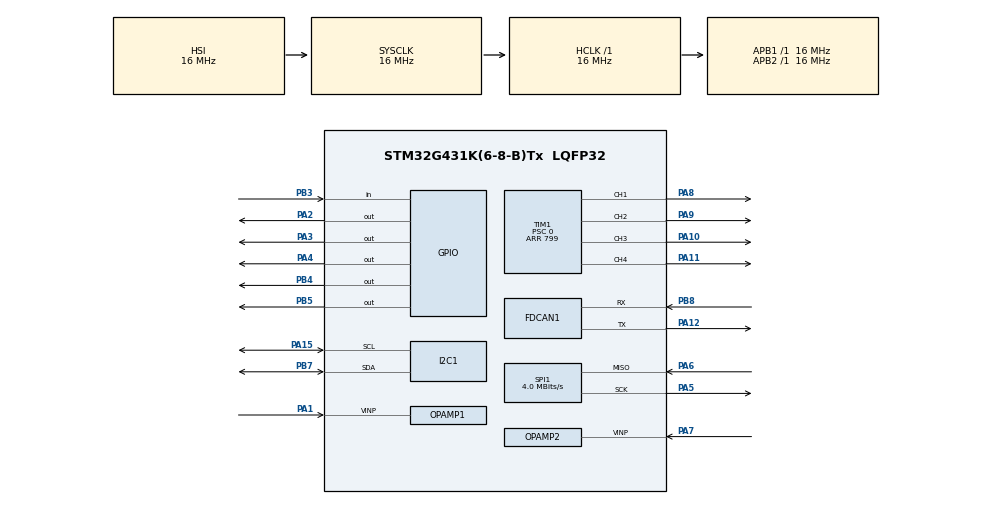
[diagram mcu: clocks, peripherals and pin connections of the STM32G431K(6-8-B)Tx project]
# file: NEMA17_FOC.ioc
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ADC1.Channel-1\#ChannelRegularConversion=ADC_CHANNEL_VOPAMP1
ADC1.NbrOfConversionFlag=1
ADC1.OffsetNumber-1\#ChannelRegularConversion=ADC_OFFSET_NONE
ADC1.Rank-1\#ChannelRegularConversion=1
ADC1.SamplingTime-1\#ChannelRegularConversion=ADC_SAMPLETIME_2CYCLES_5
ADC1.master=1
ADC2.Channel-4\#ChannelRegularConversion=ADC_CHANNEL_VOPAMP2
ADC2.NbrOfConversionFlag=1
ADC2.OffsetNumber-4\#ChannelRegularConversion=ADC_OFFSET_NONE
ADC2.Rank-4\#ChannelRegularConversion=1
ADC2.SamplingTime-4\#ChannelRegularConversion=ADC_SAMPLETIME_2CYCLES_5
FDCAN1.CalculateBaudRateNominal=333333
FDCAN1.CalculateTimeBitNominal=3000
FDCAN1.CalculateTimeQuantumNominal=1000.0
I2C1.Timing=0x00503D58
Mcu.Family=STM32G4
Mcu.Name=STM32G431K(6-8-B)Tx
Mcu.Package=LQFP32
NVIC.FDCAN1_IT0_IRQn=true\:0\:0\:false\:false\:true\:true\:true\:true
NVIC.PriorityGroup=NVIC_PRIORITYGROUP_4
NVIC.TIM2_IRQn=true\:0\:0\:false\:false\:true\:true\:true\:true
PA1.Mode=PGA_Internally_Connected
PA1.Signal=OPAMP1_VINP
PA10.Signal=S_TIM1_CH3
PA11.Signal=S_TIM1_CH4
PA12.Mode=FDCAN_Activate
PA12.Signal=FDCAN1_TX
PA13.Mode=Serial_Wire
PA13.Signal=SYS_JTMS-SWDIO
PA14.Mode=Serial_Wire
PA14.Signal=SYS_JTCK-SWCLK
PA15.Mode=I2C
PA15.Signal=I2C1_SCL
PA2.Signal=GPIO_Output
PA3.Signal=GPIO_Output
PA4.Signal=GPIO_Output
PA5.Mode=RX_Only_Simplex_Unidirect_Master
PA5.Signal=SPI1_SCK
PA6.Mode=RX_Only_Simplex_Unidirect_Master
PA6.Signal=SPI1_MISO
PA7.Mode=PGA_Internally_Connected
PA7.Signal=OPAMP2_VINP
PA8.Signal=S_TIM1_CH1
PA9.Signal=S_TIM1_CH2
PB3.Signal=GPIO_Input
PB4.Signal=GPIO_Output
PB5.Signal=GPIO_Output
PB7.Mode=I2C
PB7.Signal=I2C1_SDA
PB8-BOOT0.Mode=FDCAN_Activate
PB8-BOOT0.Signal=FDCAN1_RX
ProjectManager.HeapSize=0x200
ProjectManager.StackSize=0x400
ProjectManager.TargetToolchain=CMake
RCC.AHBFreq_Value=16000000
RCC.APB1Freq_Value=16000000
RCC.APB1TimFreq_Value=16000000
RCC.APB2Freq_Value=16000000
RCC.APB2TimFreq_Value=16000000
RCC.CortexFreq_Value=16000000
RCC.EXTERNAL_CLOCK_VALUE=12288000
RCC.HCLKFreq_Value=16000000
RCC.HSE_VALUE=8000000
RCC.HSI48_VALUE=48000000
RCC.HSI_VALUE=16000000
RCC.LSE_VALUE=32768
RCC.SYSCLKFreq_VALUE=16000000
RCC.USBFreq_Value=64000000
RCC.VCOOutputFreq_Value=128000000
SH.S_TIM1_CH1.0=TIM1_CH1,PWM Generation1 CH1
SH.S_TIM1_CH2.0=TIM1_CH2,PWM Generation2 CH2
SH.S_TIM1_CH3.0=TIM1_CH3,PWM Generation3 CH3
SH.S_TIM1_CH4.0=TIM1_CH4,PWM Generation4 CH4
SPI1.BaudRatePrescaler=SPI_BAUDRATEPRESCALER_4
SPI1.CLKPhase=SPI_PHASE_2EDGE
SPI1.CLKPolarity=SPI_POLARITY_HIGH
SPI1.CalculateBaudRate=4.0 MBits/s
SPI1.DataSize=SPI_DATASIZE_8BIT
SPI1.Direction=SPI_DIRECTION_2LINES_RXONLY
SPI1.Mode=SPI_MODE_MASTER
SPI1.VirtualType=VM_MASTER
TIM1.AutoReloadPreload=TIM_AUTORELOAD_PRELOAD_ENABLE
TIM1.Channel-PWM\ Generation1\ CH1=TIM_CHANNEL_1
TIM1.Channel-PWM\ Generation2\ CH2=TIM_CHANNEL_2
TIM1.Channel-PWM\ Generation3\ CH3=TIM_CHANNEL_3
TIM1.Channel-PWM\ Generation4\ CH4=TIM_CHANNEL_4
TIM1.CounterMode=TIM_COUNTERMODE_CENTERALIGNED1
TIM1.PeriodNoDither=799
TIM1.Prescaler=0
TIM2.PeriodNoDither=3999
TIM2.Prescaler=999
VP_ADC1_OPAMP_INTERNAL1.Mode=IN-OPAMP1
VP_ADC2_OPAMP_INTERNAL2.Mode=IN-OPAMP2
VP_CORDIC_VS_CORDIC.Mode=CORDIC_Activate
VP_SYS_VS_DBSignals.Mode=DisableDeadBatterySignals
VP_SYS_V_PVD_IN.Mode=Mode_PVD_Int
VP_TIM1_VS_ClockSourceINT.Mode=Internal
VP_TIM2_VS_ClockSourceINT.Mode=Internal
board=custom

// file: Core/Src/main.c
/* USER CODE BEGIN Header */
/**
  ******************************************************************************
  * @file           : main.c
  * @brief          : Main program body
  ******************************************************************************
  * @attention
  *
  * Copyright (c) 2026 STMicroelectronics.
  * All rights reserved.
  *
  * This software is licensed under terms that can be found in the LICENSE file
  * in the root directory of this software component.
  * If no LICENSE file comes with this software, it is provided AS-IS.
  *
  ******************************************************************************
  */
/* USER CODE END Header */
#include "main.h"

/* USER CODE BEGIN PD */
#define PWM_RANGE 1000   // Muss dem ARR Wert im CubeMX entsprechen
#define STEP_SPEED 0.01f // Erhöhen für schnellere Drehung
/* USER CODE END PD */

ADC_HandleTypeDef hadc1;
ADC_HandleTypeDef hadc2;

CORDIC_HandleTypeDef hcordic;

FDCAN_HandleTypeDef hfdcan1;

I2C_HandleTypeDef hi2c1;

OPAMP_HandleTypeDef hopamp1;
OPAMP_HandleTypeDef hopamp2;

SPI_HandleTypeDef hspi1;

TIM_HandleTypeDef htim1;
TIM_HandleTypeDef htim2;

void SystemClock_Config(void);
static void MX_GPIO_Init(void);
static void MX_SPI1_Init(void);
static void MX_TIM1_Init(void);
static void MX_TIM2_Init(void);
static void MX_CORDIC_Init(void);
static void MX_FDCAN1_Init(void);
static void MX_ADC1_Init(void);
static void MX_ADC2_Init(void);
static void MX_I2C1_Init(void);
static void MX_OPAMP1_Init(void);
static void MX_OPAMP2_Init(void);

int main(void)
{

  /* MCU Configuration--------------------------------------------------------*/

  /* Reset of all peripherals, Initializes the Flash interface and the Systick. */
  HAL_Init();

  /* Configure the system clock */
  SystemClock_Config();

  /* Initialize all configured peripherals */
  MX_GPIO_Init();
  MX_SPI1_Init();
  MX_TIM1_Init();
  MX_TIM2_Init();
  MX_CORDIC_Init();
  MX_FDCAN1_Init();
  MX_ADC1_Init();
  MX_ADC2_Init();
  MX_I2C1_Init();
  MX_OPAMP1_Init();
  MX_OPAMP2_Init();

  /* Infinite loop */
  /* USER CODE BEGIN WHILE */
  HAL_TIM_PWM_Start(&htim1, TIM_CHANNEL_1);
  HAL_TIM_PWM_Start(&htim1, TIM_CHANNEL_2);
  HAL_TIM_PWM_Start(&htim1, TIM_CHANNEL_3);
  HAL_TIM_PWM_Start(&htim1, TIM_CHANNEL_4);
  float angle = 0.0f;
  const float step_speed = 0.1f; // Erhöhen für schnellere Drehung
  const uint32_t range = 1000;    // Dein ARR Wert
  float amplitude = 0.15f;
  HAL_GPIO_WritePin(GPIOA, GPIO_PIN_6, GPIO_PIN_SET);
  HAL_GPIO_WritePin(GPIOB, GPIO_PIN_6, GPIO_PIN_SET);
  HAL_GPIO_WritePin(GPIOB, GPIO_PIN_7, GPIO_PIN_SET);

  __HAL_TIM_MOE_ENABLE(&htim1);
  /* USER CODE END 2 */

  /* Infinite loop */
  /* USER CODE BEGIN WHILE */
  while (1) {
    /* USER CODE END WHILE */

  }
}

void SystemClock_Config(void)
{
  RCC_OscInitTypeDef RCC_OscInitStruct = {0};
  RCC_ClkInitTypeDef RCC_ClkInitStruct = {0};

  /** Configure the main internal regulator output voltage
  */
  HAL_PWREx_ControlVoltageScaling(PWR_REGULATOR_VOLTAGE_SCALE1);

  /** Initializes the RCC Oscillators according to the specified parameters
  * in the RCC_OscInitTypeDef structure.
  */
  RCC_OscInitStruct.OscillatorType = RCC_OSCILLATORTYPE_HSI;
  RCC_OscInitStruct.HSIState = RCC_HSI_ON;
  RCC_OscInitStruct.HSICalibrationValue = RCC_HSICALIBRATION_DEFAULT;
  RCC_OscInitStruct.PLL.PLLState = RCC_PLL_NONE;
  if (HAL_RCC_OscConfig(&RCC_OscInitStruct) != HAL_OK)
  {
    Error_Handler();
  }

  /** Initializes the CPU, AHB and APB buses clocks
  */
  RCC_ClkInitStruct.ClockType = RCC_CLOCKTYPE_HCLK|RCC_CLOCKTYPE_SYSCLK
                              |RCC_CLOCKTYPE_PCLK1|RCC_CLOCKTYPE_PCLK2;
  RCC_ClkInitStruct.SYSCLKSource = RCC_SYSCLKSOURCE_HSI;
  RCC_ClkInitStruct.AHBCLKDivider = RCC_SYSCLK_DIV1;
  RCC_ClkInitStruct.APB1CLKDivider = RCC_HCLK_DIV1;
  RCC_ClkInitStruct.APB2CLKDivider = RCC_HCLK_DIV1;

  if (HAL_RCC_ClockConfig(&RCC_ClkInitStruct, FLASH_LATENCY_0) != HAL_OK)
  {
    Error_Handler();
  }
}

static void MX_ADC1_Init(void)
{

  ADC_MultiModeTypeDef multimode = {0};
  ADC_ChannelConfTypeDef sConfig = {0};

  /** Common config
  */
  hadc1.Instance = ADC1;
  hadc1.Init.ClockPrescaler = ADC_CLOCK_SYNC_PCLK_DIV2;
  hadc1.Init.Resolution = ADC_RESOLUTION_12B;
  hadc1.Init.DataAlign = ADC_DATAALIGN_RIGHT;
  hadc1.Init.GainCompensation = 0;
  hadc1.Init.ScanConvMode = ADC_SCAN_DISABLE;
  hadc1.Init.EOCSelection = ADC_EOC_SINGLE_CONV;
  hadc1.Init.LowPowerAutoWait = DISABLE;
  hadc1.Init.ContinuousConvMode = DISABLE;
  hadc1.Init.NbrOfConversion = 1;
  hadc1.Init.DiscontinuousConvMode = DISABLE;
  hadc1.Init.ExternalTrigConv = ADC_SOFTWARE_START;
  hadc1.Init.ExternalTrigConvEdge = ADC_EXTERNALTRIGCONVEDGE_NONE;
  hadc1.Init.DMAContinuousRequests = DISABLE;
  hadc1.Init.Overrun = ADC_OVR_DATA_PRESERVED;
  hadc1.Init.OversamplingMode = DISABLE;
  if (HAL_ADC_Init(&hadc1) != HAL_OK)
  {
    Error_Handler();
  }

  /** Configure the ADC multi-mode
  */
  multimode.Mode = ADC_MODE_INDEPENDENT;
  if (HAL_ADCEx_MultiModeConfigChannel(&hadc1, &multimode) != HAL_OK)
  {
    Error_Handler();
  }

  /** Configure Regular Channel
  */
  sConfig.Channel = ADC_CHANNEL_VOPAMP1;
  sConfig.Rank = ADC_REGULAR_RANK_1;
  sConfig.SamplingTime = ADC_SAMPLETIME_2CYCLES_5;
  sConfig.SingleDiff = ADC_SINGLE_ENDED;
  sConfig.OffsetNumber = ADC_OFFSET_NONE;
  sConfig.Offset = 0;
  if (HAL_ADC_ConfigChannel(&hadc1, &sConfig) != HAL_OK)
  {
    Error_Handler();
  }

}

static void MX_ADC2_Init(void)
{

  ADC_ChannelConfTypeDef sConfig = {0};

  /** Common config
  */
  hadc2.Instance = ADC2;
  hadc2.Init.ClockPrescaler = ADC_CLOCK_SYNC_PCLK_DIV2;
  hadc2.Init.Resolution = ADC_RESOLUTION_12B;
  hadc2.Init.DataAlign = ADC_DATAALIGN_RIGHT;
  hadc2.Init.GainCompensation = 0;
  hadc2.Init.ScanConvMode = ADC_SCAN_DISABLE;
  hadc2.Init.EOCSelection = ADC_EOC_SINGLE_CONV;
  hadc2.Init.LowPowerAutoWait = DISABLE;
  hadc2.Init.ContinuousConvMode = DISABLE;
  hadc2.Init.NbrOfConversion = 1;
  hadc2.Init.DiscontinuousConvMode = DISABLE;
  hadc2.Init.ExternalTrigConv = ADC_SOFTWARE_START;
  hadc2.Init.ExternalTrigConvEdge = ADC_EXTERNALTRIGCONVEDGE_NONE;
  hadc2.Init.DMAContinuousRequests = DISABLE;
  hadc2.Init.Overrun = ADC_OVR_DATA_PRESERVED;
  hadc2.Init.OversamplingMode = DISABLE;
  if (HAL_ADC_Init(&hadc2) != HAL_OK)
  {
    Error_Handler();
  }

  /** Configure Regular Channel
  */
  sConfig.Channel = ADC_CHANNEL_VOPAMP2;
  sConfig.Rank = ADC_REGULAR_RANK_1;
  sConfig.SamplingTime = ADC_SAMPLETIME_2CYCLES_5;
  sConfig.SingleDiff = ADC_SINGLE_ENDED;
  sConfig.OffsetNumber = ADC_OFFSET_NONE;
  sConfig.Offset = 0;
  if (HAL_ADC_ConfigChannel(&hadc2, &sConfig) != HAL_OK)
  {
    Error_Handler();
  }

}

static void MX_CORDIC_Init(void)
{

  hcordic.Instance = CORDIC;
  if (HAL_CORDIC_Init(&hcordic) != HAL_OK)
  {
    Error_Handler();
  }

}

static void MX_FDCAN1_Init(void)
{

  hfdcan1.Instance = FDCAN1;
  hfdcan1.Init.ClockDivider = FDCAN_CLOCK_DIV1;
  hfdcan1.Init.FrameFormat = FDCAN_FRAME_CLASSIC;
  hfdcan1.Init.Mode = FDCAN_MODE_NORMAL;
  hfdcan1.Init.AutoRetransmission = DISABLE;
  hfdcan1.Init.TransmitPause = DISABLE;
  hfdcan1.Init.ProtocolException = DISABLE;
  hfdcan1.Init.NominalPrescaler = 16;
  hfdcan1.Init.NominalSyncJumpWidth = 1;
  hfdcan1.Init.NominalTimeSeg1 = 1;
  hfdcan1.Init.NominalTimeSeg2 = 1;
  hfdcan1.Init.DataPrescaler = 1;
  hfdcan1.Init.DataSyncJumpWidth = 1;
  hfdcan1.Init.DataTimeSeg1 = 1;
  hfdcan1.Init.DataTimeSeg2 = 1;
  hfdcan1.Init.StdFiltersNbr = 0;
  hfdcan1.Init.ExtFiltersNbr = 0;
  hfdcan1.Init.TxFifoQueueMode = FDCAN_TX_FIFO_OPERATION;
  if (HAL_FDCAN_Init(&hfdcan1) != HAL_OK)
  {
    Error_Handler();
  }

}

static void MX_I2C1_Init(void)
{

  hi2c1.Instance = I2C1;
  hi2c1.Init.Timing = 0x00503D58;
  hi2c1.Init.OwnAddress1 = 0;
  hi2c1.Init.AddressingMode = I2C_ADDRESSINGMODE_7BIT;
  hi2c1.Init.DualAddressMode = I2C_DUALADDRESS_DISABLE;
  hi2c1.Init.OwnAddress2 = 0;
  hi2c1.Init.OwnAddress2Masks = I2C_OA2_NOMASK;
  hi2c1.Init.GeneralCallMode = I2C_GENERALCALL_DISABLE;
  hi2c1.Init.NoStretchMode = I2C_NOSTRETCH_DISABLE;
  if (HAL_I2C_Init(&hi2c1) != HAL_OK)
  {
    Error_Handler();
  }

  /** Configure Analogue filter
  */
  if (HAL_I2CEx_ConfigAnalogFilter(&hi2c1, I2C_ANALOGFILTER_ENABLE) != HAL_OK)
  {
    Error_Handler();
  }

  /** Configure Digital filter
  */
  if (HAL_I2CEx_ConfigDigitalFilter(&hi2c1, 0) != HAL_OK)
  {
    Error_Handler();
  }

}

static void MX_OPAMP1_Init(void)
{

  hopamp1.Instance = OPAMP1;
  hopamp1.Init.PowerMode = OPAMP_POWERMODE_NORMALSPEED;
  hopamp1.Init.Mode = OPAMP_PGA_MODE;
  hopamp1.Init.NonInvertingInput = OPAMP_NONINVERTINGINPUT_IO0;
  hopamp1.Init.InternalOutput = ENABLE;
  hopamp1.Init.TimerControlledMuxmode = OPAMP_TIMERCONTROLLEDMUXMODE_DISABLE;
  hopamp1.Init.PgaConnect = OPAMP_PGA_CONNECT_INVERTINGINPUT_NO;
  hopamp1.Init.PgaGain = OPAMP_PGA_GAIN_2_OR_MINUS_1;
  hopamp1.Init.UserTrimming = OPAMP_TRIMMING_FACTORY;
  if (HAL_OPAMP_Init(&hopamp1) != HAL_OK)
  {
    Error_Handler();
  }

}

static void MX_OPAMP2_Init(void)
{

  hopamp2.Instance = OPAMP2;
  hopamp2.Init.PowerMode = OPAMP_POWERMODE_NORMALSPEED;
  hopamp2.Init.Mode = OPAMP_PGA_MODE;
  hopamp2.Init.NonInvertingInput = OPAMP_NONINVERTINGINPUT_IO0;
  hopamp2.Init.InternalOutput = ENABLE;
  hopamp2.Init.TimerControlledMuxmode = OPAMP_TIMERCONTROLLEDMUXMODE_DISABLE;
  hopamp2.Init.PgaConnect = OPAMP_PGA_CONNECT_INVERTINGINPUT_NO;
  hopamp2.Init.PgaGain = OPAMP_PGA_GAIN_2_OR_MINUS_1;
  hopamp2.Init.UserTrimming = OPAMP_TRIMMING_FACTORY;
  if (HAL_OPAMP_Init(&hopamp2) != HAL_OK)
  {
    Error_Handler();
  }

}

static void MX_SPI1_Init(void)
{

  /* SPI1 parameter configuration*/
  hspi1.Instance = SPI1;
  hspi1.Init.Mode = SPI_MODE_MASTER;
  hspi1.Init.Direction = SPI_DIRECTION_2LINES_RXONLY;
  hspi1.Init.DataSize = SPI_DATASIZE_8BIT;
  hspi1.Init.CLKPolarity = SPI_POLARITY_HIGH;
  hspi1.Init.CLKPhase = SPI_PHASE_2EDGE;
  hspi1.Init.NSS = SPI_NSS_SOFT;
  hspi1.Init.BaudRatePrescaler = SPI_BAUDRATEPRESCALER_4;
  hspi1.Init.FirstBit = SPI_FIRSTBIT_MSB;
  hspi1.Init.TIMode = SPI_TIMODE_DISABLE;
  hspi1.Init.CRCCalculation = SPI_CRCCALCULATION_DISABLE;
  hspi1.Init.CRCPolynomial = 7;
  hspi1.Init.CRCLength = SPI_CRC_LENGTH_DATASIZE;
  hspi1.Init.NSSPMode = SPI_NSS_PULSE_DISABLE;
  if (HAL_SPI_Init(&hspi1) != HAL_OK)
  {
    Error_Handler();
  }

}

static void MX_TIM1_Init(void)
{

  TIM_ClockConfigTypeDef sClockSourceConfig = {0};
  TIM_MasterConfigTypeDef sMasterConfig = {0};
  TIM_OC_InitTypeDef sConfigOC = {0};
  TIM_BreakDeadTimeConfigTypeDef sBreakDeadTimeConfig = {0};

  htim1.Instance = TIM1;
  htim1.Init.Prescaler = 0;
  htim1.Init.CounterMode = TIM_COUNTERMODE_CENTERALIGNED1;
  htim1.Init.Period = 799;
  htim1.Init.ClockDivision = TIM_CLOCKDIVISION_DIV1;
  htim1.Init.RepetitionCounter = 0;
  htim1.Init.AutoReloadPreload = TIM_AUTORELOAD_PRELOAD_ENABLE;
  if (HAL_TIM_Base_Init(&htim1) != HAL_OK)
  {
    Error_Handler();
  }
  sClockSourceConfig.ClockSource = TIM_CLOCKSOURCE_INTERNAL;
  if (HAL_TIM_ConfigClockSource(&htim1, &sClockSourceConfig) != HAL_OK)
  {
    Error_Handler();
  }
  if (HAL_TIM_PWM_Init(&htim1) != HAL_OK)
  {
    Error_Handler();
  }
  sMasterConfig.MasterOutputTrigger = TIM_TRGO_RESET;
  sMasterConfig.MasterOutputTrigger2 = TIM_TRGO2_RESET;
  sMasterConfig.MasterSlaveMode = TIM_MASTERSLAVEMODE_DISABLE;
  if (HAL_TIMEx_MasterConfigSynchronization(&htim1, &sMasterConfig) != HAL_OK)
  {
    Error_Handler();
  }
  sConfigOC.OCMode = TIM_OCMODE_PWM1;
  sConfigOC.Pulse = 0;
  sConfigOC.OCPolarity = TIM_OCPOLARITY_HIGH;
  sConfigOC.OCNPolarity = TIM_OCNPOLARITY_HIGH;
  sConfigOC.OCFastMode = TIM_OCFAST_DISABLE;
  sConfigOC.OCIdleState = TIM_OCIDLESTATE_RESET;
  sConfigOC.OCNIdleState = TIM_OCNIDLESTATE_RESET;
  if (HAL_TIM_PWM_ConfigChannel(&htim1, &sConfigOC, TIM_CHANNEL_1) != HAL_OK)
  {
    Error_Handler();
  }
  if (HAL_TIM_PWM_ConfigChannel(&htim1, &sConfigOC, TIM_CHANNEL_2) != HAL_OK)
  {
    Error_Handler();
  }
  if (HAL_TIM_PWM_ConfigChannel(&htim1, &sConfigOC, TIM_CHANNEL_3) != HAL_OK)
  {
    Error_Handler();
  }
  if (HAL_TIM_PWM_ConfigChannel(&htim1, &sConfigOC, TIM_CHANNEL_4) != HAL_OK)
  {
    Error_Handler();
  }
  sBreakDeadTimeConfig.OffStateRunMode = TIM_OSSR_DISABLE;
  sBreakDeadTimeConfig.OffStateIDLEMode = TIM_OSSI_DISABLE;
  sBreakDeadTimeConfig.LockLevel = TIM_LOCKLEVEL_OFF;
  sBreakDeadTimeConfig.DeadTime = 0;
  sBreakDeadTimeConfig.BreakState = TIM_BREAK_DISABLE;
  sBreakDeadTimeConfig.BreakPolarity = TIM_BREAKPOLARITY_HIGH;
  sBreakDeadTimeConfig.BreakFilter = 0;
  sBreakDeadTimeConfig.BreakAFMode = TIM_BREAK_AFMODE_INPUT;
  sBreakDeadTimeConfig.Break2State = TIM_BREAK2_DISABLE;
  sBreakDeadTimeConfig.Break2Polarity = TIM_BREAK2POLARITY_HIGH;
  sBreakDeadTimeConfig.Break2Filter = 0;
  sBreakDeadTimeConfig.Break2AFMode = TIM_BREAK_AFMODE_INPUT;
  sBreakDeadTimeConfig.AutomaticOutput = TIM_AUTOMATICOUTPUT_DISABLE;
  if (HAL_TIMEx_ConfigBreakDeadTime(&htim1, &sBreakDeadTimeConfig) != HAL_OK)
  {
    Error_Handler();
  }
  HAL_TIM_MspPostInit(&htim1);

}

static void MX_TIM2_Init(void)
{

  TIM_ClockConfigTypeDef sClockSourceConfig = {0};
  TIM_MasterConfigTypeDef sMasterConfig = {0};

  htim2.Instance = TIM2;
  htim2.Init.Prescaler = 999;
  htim2.Init.CounterMode = TIM_COUNTERMODE_UP;
  htim2.Init.Period = 3999;
  htim2.Init.ClockDivision = TIM_CLOCKDIVISION_DIV1;
  htim2.Init.AutoReloadPreload = TIM_AUTORELOAD_PRELOAD_DISABLE;
  if (HAL_TIM_Base_Init(&htim2) != HAL_OK)
  {
    Error_Handler();
  }
  sClockSourceConfig.ClockSource = TIM_CLOCKSOURCE_INTERNAL;
  if (HAL_TIM_ConfigClockSource(&htim2, &sClockSourceConfig) != HAL_OK)
  {
    Error_Handler();
  }
  sMasterConfig.MasterOutputTrigger = TIM_TRGO_RESET;
  sMasterConfig.MasterSlaveMode = TIM_MASTERSLAVEMODE_DISABLE;
  if (HAL_TIMEx_MasterConfigSynchronization(&htim2, &sMasterConfig) != HAL_OK)
  {
    Error_Handler();
  }

}

static void MX_GPIO_Init(void)
{
  GPIO_InitTypeDef GPIO_InitStruct = {0};

  /* GPIO Ports Clock Enable */
  __HAL_RCC_GPIOA_CLK_ENABLE();
  __HAL_RCC_GPIOB_CLK_ENABLE();

  /*Configure GPIO pin Output Level */
  HAL_GPIO_WritePin(GPIOA, GPIO_PIN_2|GPIO_PIN_3|GPIO_PIN_4, GPIO_PIN_RESET);

  /*Configure GPIO pin Output Level */
  HAL_GPIO_WritePin(GPIOB, GPIO_PIN_4|GPIO_PIN_5, GPIO_PIN_RESET);

  /*Configure GPIO pins : PA2 PA3 PA4 */
  GPIO_InitStruct.Pin = GPIO_PIN_2|GPIO_PIN_3|GPIO_PIN_4;
  GPIO_InitStruct.Mode = GPIO_MODE_OUTPUT_PP;
  GPIO_InitStruct.Pull = GPIO_NOPULL;
  GPIO_InitStruct.Speed = GPIO_SPEED_FREQ_LOW;
  HAL_GPIO_Init(GPIOA, &GPIO_InitStruct);

  /*Configure GPIO pin : PB3 */
  GPIO_InitStruct.Pin = GPIO_PIN_3;
  GPIO_InitStruct.Mode = GPIO_MODE_INPUT;
  GPIO_InitStruct.Pull = GPIO_NOPULL;
  HAL_GPIO_Init(GPIOB, &GPIO_InitStruct);

  /*Configure GPIO pins : PB4 PB5 */
  GPIO_InitStruct.Pin = GPIO_PIN_4|GPIO_PIN_5;
  GPIO_InitStruct.Mode = GPIO_MODE_OUTPUT_PP;
  GPIO_InitStruct.Pull = GPIO_NOPULL;
  GPIO_InitStruct.Speed = GPIO_SPEED_FREQ_LOW;
  HAL_GPIO_Init(GPIOB, &GPIO_InitStruct);

}

void Error_Handler(void)
{
  __disable_irq();
  while (1)
  {
  }
}
